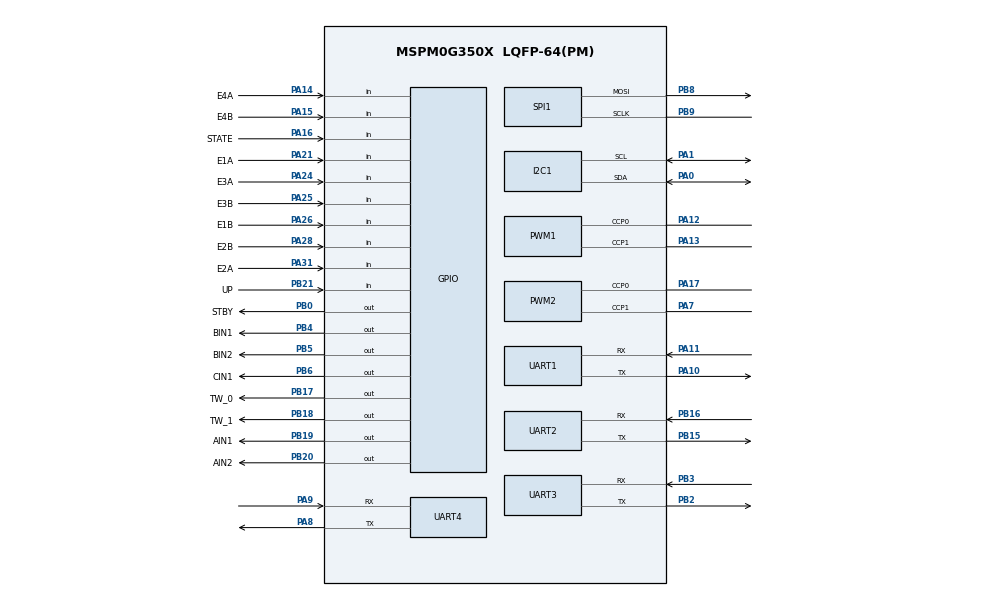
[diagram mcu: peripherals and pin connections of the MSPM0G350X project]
/**
 * @cliArgs --device "MSPM0G350X" --part "Default" --package "LQFP-64(PM)" --product "mspm0_sdk@2.02.00.05"
 * @versions {"tool":"1.21.1+3772"}
 */

/**
 * Import the modules used in this configuration.
 */
const ADC12   = scripting.addModule("/ti/driverlib/ADC12", {}, false);
const ADC121  = ADC12.addInstance();
const GPIO    = scripting.addModule("/ti/driverlib/GPIO", {}, false);
const GPIO1   = GPIO.addInstance();
const GPIO2   = GPIO.addInstance();
const GPIO3   = GPIO.addInstance();
const GPIO4   = GPIO.addInstance();
const GPIO5   = GPIO.addInstance();
const GPIO6   = GPIO.addInstance();
const I2C     = scripting.addModule("/ti/driverlib/I2C", {}, false);
const I2C1    = I2C.addInstance();
const PWM     = scripting.addModule("/ti/driverlib/PWM", {}, false);
const PWM1    = PWM.addInstance();
const PWM2    = PWM.addInstance();
const SPI     = scripting.addModule("/ti/driverlib/SPI", {}, false);
const SPI1    = SPI.addInstance();
const SYSCTL  = scripting.addModule("/ti/driverlib/SYSCTL");
const SYSTICK = scripting.addModule("/ti/driverlib/SYSTICK");
const TIMER   = scripting.addModule("/ti/driverlib/TIMER", {}, false);
const TIMER1  = TIMER.addInstance();
const UART    = scripting.addModule("/ti/driverlib/UART", {}, false);
const UART1   = UART.addInstance();
const UART2   = UART.addInstance();
const UART3   = UART.addInstance();
const UART4   = UART.addInstance();

/**
 * Write custom configuration values to the imported modules.
 */
const divider9       = system.clockTree["UDIV"];
divider9.divideValue = 2;

const gate7  = system.clockTree["MFCLKGATE"];
gate7.enable = true;

const multiplier2         = system.clockTree["PLL_QDIV"];
multiplier2.multiplyValue = 5;

const mux8       = system.clockTree["HSCLKMUX"];
mux8.inputSelect = "HSCLKMUX_SYSPLL0";

ADC121.$name                             = "ADC_VOLTAGE";
ADC121.repeatMode                        = true;
ADC121.adcMem0_name                      = "ADC_CH0";
ADC121.sampClkDiv                        = "DL_ADC12_CLOCK_DIVIDE_8";
ADC121.powerDownMode                     = "DL_ADC12_POWER_DOWN_MODE_MANUAL";
ADC121.sampleTime0                       = "10ms";
ADC121.enabledInterrupts                 = ["DL_ADC12_INTERRUPT_MEM0_RESULT_LOADED"];
ADC121.peripheral.$assign                = "ADC0";
ADC121.peripheral.adcPin0.$assign        = "PA27";
ADC121.adcPin0Config.hideOutputInversion = scripting.forceWrite(false);
ADC121.adcPin0Config.$name               = "ti_driverlib_gpio_GPIOPinGeneric8";

const Board = scripting.addModule("/ti/driverlib/Board", {}, false);

/* LCD data bus: hardware SPI1 (SCLK=PB9, PICO=PB8), MOTO3, POCI unused -> left unassigned */
SPI1.$name                              = "LCD_DATA";
SPI1.frameFormat                        = "MOTO3";
SPI1.direction                          = "PICO";   /* 只发不收: 不占用 POCI, 把 PB21 让给按键 */
SPI1.targetBitRate                      = 32000000;
SPI1.peripheral.$assign                 = "SPI1";
SPI1.peripheral.sclkPin.$assign         = "PB9";
SPI1.peripheral.mosiPin.$assign         = "PB8";
SPI1.sclkPinConfig.direction            = scripting.forceWrite("OUTPUT");
SPI1.sclkPinConfig.onlyInternalResistor = scripting.forceWrite(false);
SPI1.sclkPinConfig.passedPeripheralType = scripting.forceWrite("Digital");
SPI1.mosiPinConfig.direction            = scripting.forceWrite("OUTPUT");
SPI1.mosiPinConfig.hideOutputInversion  = scripting.forceWrite(false);
SPI1.mosiPinConfig.onlyInternalResistor = scripting.forceWrite(false);
SPI1.mosiPinConfig.passedPeripheralType = scripting.forceWrite("Digital");
SPI1.sclkPinConfig.$name                = "ti_driverlib_gpio_GPIOPinGeneric15";
SPI1.mosiPinConfig.$name                = "ti_driverlib_gpio_GPIOPinGeneric16";
GPIO1.$name                          = "LCD";
GPIO1.port                           = "PORTB";
GPIO1.associatedPins.create(4);
GPIO1.associatedPins[0].$name        = "LCD_RES";
GPIO1.associatedPins[0].assignedPort = "PORTB";
GPIO1.associatedPins[0].assignedPin  = "10";
GPIO1.associatedPins[1].$name        = "LCD_DC";
GPIO1.associatedPins[1].assignedPort = "PORTB";
GPIO1.associatedPins[1].assignedPin  = "11";
GPIO1.associatedPins[2].$name        = "LCD_CS";
GPIO1.associatedPins[2].assignedPort = "PORTB";
GPIO1.associatedPins[2].assignedPin  = "14";
GPIO1.associatedPins[3].$name        = "BLK";
GPIO1.associatedPins[3].assignedPort = "PORTB";
GPIO1.associatedPins[3].assignedPin  = "26";
GPIO2.$name                         = "Motor";
GPIO2.port                          = "PORTB";
GPIO2.associatedPins.create(9);
GPIO2.associatedPins[0].$name       = "AIN1";
GPIO2.associatedPins[0].assignedPin = "19";
GPIO2.associatedPins[0].pin.$assign = "PB19";
GPIO2.associatedPins[1].$name       = "AIN2";
GPIO2.associatedPins[1].assignedPin = "20";
GPIO2.associatedPins[1].pin.$assign = "PB20";
GPIO2.associatedPins[2].$name       = "BIN1";
GPIO2.associatedPins[2].assignedPin = "4";
GPIO2.associatedPins[2].pin.$assign = "PB4";
GPIO2.associatedPins[3].$name       = "BIN2";
GPIO2.associatedPins[3].assignedPin = "5";
GPIO2.associatedPins[3].pin.$assign = "PB5";
GPIO2.associatedPins[4].$name       = "CIN1";
GPIO2.associatedPins[4].assignedPin = "6";
GPIO2.associatedPins[4].pin.$assign = "PB6";
GPIO2.associatedPins[5].assignedPin = "7";
GPIO2.associatedPins[5].$name       = "CIN2";
GPIO2.associatedPins[6].assignedPin = "12";
GPIO2.associatedPins[6].$name       = "DIN1";
GPIO2.associatedPins[7].assignedPin = "13";
GPIO2.associatedPins[7].$name       = "DIN2";
GPIO2.associatedPins[8].$name       = "STBY";   /* TB6612 enable, active high */
GPIO2.associatedPins[8].assignedPort = "PORTB";
GPIO2.associatedPins[8].assignedPin = "0";
GPIO2.associatedPins[8].pin.$assign = "PB0";

GPIO3.$name                               = "ENCODER";
GPIO3.associatedPins.create(8);
GPIO3.associatedPins[0].direction         = "INPUT";
GPIO3.associatedPins[0].assignedPort      = "PORTA";
GPIO3.associatedPins[0].assignedPin       = "26";
GPIO3.associatedPins[0].interruptEn       = true;
GPIO3.associatedPins[0].interruptPriority = "0";
GPIO3.associatedPins[0].polarity          = "RISE";
GPIO3.associatedPins[0].$name             = "E1B";
GPIO3.associatedPins[0].pin.$assign       = "PA26";
GPIO3.associatedPins[1].direction         = "INPUT";
GPIO3.associatedPins[1].assignedPort      = "PORTA";
GPIO3.associatedPins[1].assignedPin       = "31";
GPIO3.associatedPins[1].interruptEn       = true;
GPIO3.associatedPins[1].interruptPriority = "0";
GPIO3.associatedPins[1].polarity          = "RISE";
GPIO3.associatedPins[1].$name             = "E2A";
GPIO3.associatedPins[1].pin.$assign       = "PA31";
GPIO3.associatedPins[2].$name             = "E2B";
GPIO3.associatedPins[2].direction         = "INPUT";
GPIO3.associatedPins[2].assignedPort      = "PORTA";
GPIO3.associatedPins[2].assignedPin       = "28";
GPIO3.associatedPins[2].interruptEn       = true;
GPIO3.associatedPins[2].polarity          = "RISE";
GPIO3.associatedPins[2].pin.$assign       = "PA28";
GPIO3.associatedPins[3].assignedPort      = "PORTA";
GPIO3.associatedPins[3].assignedPin       = "24";
GPIO3.associatedPins[3].$name             = "E3A";
GPIO3.associatedPins[3].direction         = "INPUT";
GPIO3.associatedPins[3].interruptEn       = true;
GPIO3.associatedPins[3].polarity          = "RISE";
GPIO3.associatedPins[3].pin.$assign       = "PA24";
GPIO3.associatedPins[4].assignedPort      = "PORTA";
GPIO3.associatedPins[4].assignedPin       = "25";
GPIO3.associatedPins[4].$name             = "E3B";
GPIO3.associatedPins[4].direction         = "INPUT";
GPIO3.associatedPins[4].interruptEn       = true;
GPIO3.associatedPins[4].polarity          = "RISE";
GPIO3.associatedPins[4].pin.$assign       = "PA25";
GPIO3.associatedPins[5].assignedPort      = "PORTA";
GPIO3.associatedPins[5].assignedPin       = "14";
GPIO3.associatedPins[5].direction         = "INPUT";
GPIO3.associatedPins[5].interruptEn       = true;
GPIO3.associatedPins[5].interruptPriority = "0";
GPIO3.associatedPins[5].polarity          = "RISE";
GPIO3.associatedPins[5].$name             = "E4A";
GPIO3.associatedPins[5].pin.$assign       = "PA14";
GPIO3.associatedPins[6].assignedPort      = "PORTA";
GPIO3.associatedPins[6].direction         = "INPUT";
GPIO3.associatedPins[6].assignedPin       = "15";
GPIO3.associatedPins[6].interruptEn       = true;
GPIO3.associatedPins[6].interruptPriority = "0";
GPIO3.associatedPins[6].polarity          = "RISE";
GPIO3.associatedPins[6].$name             = "E4B";
GPIO3.associatedPins[6].pin.$assign       = "PA15";
GPIO3.associatedPins[7].$name             = "E1A";
GPIO3.associatedPins[7].direction         = "INPUT";
GPIO3.associatedPins[7].assignedPort      = "PORTA";
GPIO3.associatedPins[7].interruptEn       = true;
GPIO3.associatedPins[7].polarity          = "RISE";
GPIO3.associatedPins[7].pin.$assign       = "PA21";

GPIO4.$name                          = "HCO5";
GPIO4.associatedPins[0].$name        = "STATE";
GPIO4.associatedPins[0].assignedPort = "PORTA";
GPIO4.associatedPins[0].direction    = "INPUT";
GPIO4.associatedPins[0].assignedPin  = "16";
GPIO4.associatedPins[0].pin.$assign  = "PA16";

GPIO5.$name                          = "TW";
GPIO5.associatedPins.create(2);
GPIO5.associatedPins[0].$name        = "TW_0";
GPIO5.associatedPins[0].assignedPort = "PORTB";
GPIO5.associatedPins[0].pin.$assign  = "PB17";
GPIO5.associatedPins[1].$name        = "TW_1";
GPIO5.associatedPins[1].assignedPort = "PORTB";
GPIO5.associatedPins[1].pin.$assign  = "PB18";
/* 板载按键 S2 = PB21 (按下接 GND, 内部上拉): 单击启停 / 长按加速 */
GPIO6.$name                          = "KEY1";
GPIO6.associatedPins[0].$name        = "UP";
GPIO6.associatedPins[0].assignedPort = "PORTB";
GPIO6.associatedPins[0].direction    = "INPUT";
GPIO6.associatedPins[0].internalResistor = "PULL_UP";
GPIO6.associatedPins[0].assignedPin  = "21";
GPIO6.associatedPins[0].pin.$assign  = "PB21";


I2C1.$name                           = "I2C_0";
I2C1.basicEnableController           = true;
I2C1.basicControllerStandardBusSpeed = "Fast";
I2C1.peripheral.$assign              = "I2C0";
I2C1.peripheral.sdaPin.$assign       = "PA0";
I2C1.peripheral.sclPin.$assign       = "PA1";
I2C1.sdaPinConfig.$name              = "ti_driverlib_gpio_GPIOPinGeneric11";
I2C1.sclPinConfig.$name              = "ti_driverlib_gpio_GPIOPinGeneric12";

PWM1.clockDivider                       = 4;
PWM1.clockPrescale                      = 5;
PWM1.timerStartTimer                    = true;
PWM1.$name                              = "Motor_PWM_Front";
PWM1.clockDivider                       = 4;   /* 80MHz/4/1 = 20MHz -> 20kHz PWM */
PWM1.clockPrescale                      = 1;
PWM1.peripheral.$assign                 = "TIMG0";
PWM1.peripheral.ccp0Pin.$assign         = "PA12";
PWM1.peripheral.ccp1Pin.$assign         = "PA13";
PWM1.PWM_CHANNEL_0.$name                = "ti_driverlib_pwm_PWMTimerCC0";
PWM1.PWM_CHANNEL_0.invert               = true;
PWM1.PWM_CHANNEL_1.$name                = "ti_driverlib_pwm_PWMTimerCC1";
PWM1.PWM_CHANNEL_1.invert               = true;
PWM1.ccp0PinConfig.direction            = scripting.forceWrite("OUTPUT");
PWM1.ccp0PinConfig.hideOutputInversion  = scripting.forceWrite(false);
PWM1.ccp0PinConfig.onlyInternalResistor = scripting.forceWrite(false);
PWM1.ccp0PinConfig.passedPeripheralType = scripting.forceWrite("Digital");
PWM1.ccp0PinConfig.$name                = "ti_driverlib_gpio_GPIOPinGeneric2";
PWM1.ccp1PinConfig.direction            = scripting.forceWrite("OUTPUT");
PWM1.ccp1PinConfig.hideOutputInversion  = scripting.forceWrite(false);
PWM1.ccp1PinConfig.onlyInternalResistor = scripting.forceWrite(false);
PWM1.ccp1PinConfig.passedPeripheralType = scripting.forceWrite("Digital");
PWM1.ccp1PinConfig.$name                = "ti_driverlib_gpio_GPIOPinGeneric3";

PWM2.$name                              = "Motor_PWM_Back";
PWM2.clockDivider                       = 4;
PWM2.clockPrescale                      = 1;   /* 20MHz -> 20kHz, same as front */
PWM2.timerStartTimer                    = true;
PWM2.peripheral.$assign                 = "TIMG7";
PWM2.peripheral.ccp0Pin.$assign         = "PA17";
PWM2.peripheral.ccp1Pin.$assign         = "PA7";
PWM2.PWM_CHANNEL_0.$name                = "ti_driverlib_pwm_PWMTimerCC2";
PWM2.PWM_CHANNEL_0.invert               = true;
PWM2.PWM_CHANNEL_1.$name                = "ti_driverlib_pwm_PWMTimerCC3";
PWM2.PWM_CHANNEL_1.invert               = true;
PWM2.ccp0PinConfig.direction            = scripting.forceWrite("OUTPUT");
PWM2.ccp0PinConfig.hideOutputInversion  = scripting.forceWrite(false);
PWM2.ccp0PinConfig.onlyInternalResistor = scripting.forceWrite(false);
PWM2.ccp0PinConfig.passedPeripheralType = scripting.forceWrite("Digital");
PWM2.ccp0PinConfig.$name                = "ti_driverlib_gpio_GPIOPinGeneric4";
PWM2.ccp1PinConfig.direction            = scripting.forceWrite("OUTPUT");
PWM2.ccp1PinConfig.hideOutputInversion  = scripting.forceWrite(false);
PWM2.ccp1PinConfig.onlyInternalResistor = scripting.forceWrite(false);
PWM2.ccp1PinConfig.passedPeripheralType = scripting.forceWrite("Digital");
PWM2.ccp1PinConfig.$name                = "ti_driverlib_gpio_GPIOPinGeneric5";

SYSCTL.forceDefaultClkConfig = true;
SYSCTL.clockTreeEn           = true;

SYSTICK.periodEnable  = true;
SYSTICK.period        = 80;
SYSTICK.systickEnable = true;

TIMER1.$name              = "TIMER_0";
TIMER1.timerClkDiv        = 8;
TIMER1.timerPeriod        = "1 ms";
TIMER1.timerMode          = "PERIODIC";
TIMER1.timerStartTimer    = true;
TIMER1.interrupts         = ["ZERO"];
TIMER1.peripheral.$assign = "TIMG6";

UART1.$name                    = "UART_0";
UART1.targetBaudRate           = 115200;
UART1.uartClkDiv               = "5";
UART1.enabledInterrupts        = ["RX"];
UART1.peripheral.$assign       = "UART0";
UART1.peripheral.rxPin.$assign = "PA11";
UART1.peripheral.txPin.$assign = "PA10";
UART1.txPinConfig.$name        = "ti_driverlib_gpio_GPIOPinGeneric0";
UART1.rxPinConfig.enableConfig = true;
UART1.rxPinConfig.internalResistor = "PULL_UP";   /* RX idle high when floating */
UART1.rxPinConfig.$name        = "ti_driverlib_gpio_GPIOPinGeneric1";

UART2.$name                            = "UART_2";
UART2.enabledInterrupts                = ["RX"];
UART2.targetBaudRate                   = 115200;
UART2.uartClkDiv                       = "5";
UART2.peripheral.$assign               = "UART2";
UART2.peripheral.rxPin.$assign         = "PB16";
UART2.peripheral.txPin.$assign         = "PB15";
UART2.txPinConfig.direction            = scripting.forceWrite("OUTPUT");
UART2.txPinConfig.hideOutputInversion  = scripting.forceWrite(false);
UART2.txPinConfig.onlyInternalResistor = scripting.forceWrite(false);
UART2.txPinConfig.passedPeripheralType = scripting.forceWrite("Digital");
UART2.txPinConfig.$name                = "ti_driverlib_gpio_GPIOPinGeneric6";
UART2.rxPinConfig.hideOutputInversion  = scripting.forceWrite(false);
UART2.rxPinConfig.onlyInternalResistor = scripting.forceWrite(false);
UART2.rxPinConfig.passedPeripheralType = scripting.forceWrite("Digital");
UART2.rxPinConfig.enableConfig = true;
UART2.rxPinConfig.internalResistor = "PULL_UP";   /* RX idle high when floating */
UART2.rxPinConfig.$name                = "ti_driverlib_gpio_GPIOPinGeneric7";

UART3.$name                            = "LORA";
UART3.enabledInterrupts                = ["RX"];
UART3.uartClkDiv                       = "5";
UART3.peripheral.$assign               = "UART3";
UART3.peripheral.rxPin.$assign         = "PB3";
UART3.peripheral.txPin.$assign         = "PB2";
UART3.txPinConfig.direction            = scripting.forceWrite("OUTPUT");
UART3.txPinConfig.hideOutputInversion  = scripting.forceWrite(false);
UART3.txPinConfig.onlyInternalResistor = scripting.forceWrite(false);
UART3.txPinConfig.passedPeripheralType = scripting.forceWrite("Digital");
UART3.txPinConfig.$name                = "ti_driverlib_gpio_GPIOPinGeneric9";
UART3.rxPinConfig.hideOutputInversion  = scripting.forceWrite(false);
UART3.rxPinConfig.onlyInternalResistor = scripting.forceWrite(false);
UART3.rxPinConfig.passedPeripheralType = scripting.forceWrite("Digital");
UART3.rxPinConfig.enableConfig = true;
UART3.rxPinConfig.internalResistor = "PULL_UP";   /* RX idle high when floating */
UART3.rxPinConfig.$name                = "ti_driverlib_gpio_GPIOPinGeneric10";

UART4.targetBaudRate                   = 115200;
UART4.uartClkDiv                       = "5";
UART4.$name                            = "IMU";
UART4.enabledInterrupts                = ["RX"];
UART4.peripheral.$assign               = "UART1";
UART4.peripheral.rxPin.$assign         = "PA9";
UART4.peripheral.txPin.$assign         = "PA8";
UART4.txPinConfig.$name                = "ti_driverlib_gpio_GPIOPinGeneric13";
UART4.txPinConfig.direction            = scripting.forceWrite("OUTPUT");
UART4.txPinConfig.hideOutputInversion  = scripting.forceWrite(false);
UART4.txPinConfig.onlyInternalResistor = scripting.forceWrite(false);
UART4.txPinConfig.passedPeripheralType = scripting.forceWrite("Digital");
UART4.rxPinConfig.enableConfig = true;
UART4.rxPinConfig.internalResistor = "PULL_UP";   /* RX idle high when floating */
UART4.rxPinConfig.$name                = "ti_driverlib_gpio_GPIOPinGeneric14";
UART4.rxPinConfig.hideOutputInversion  = scripting.forceWrite(false);
UART4.rxPinConfig.onlyInternalResistor = scripting.forceWrite(false);
UART4.rxPinConfig.passedPeripheralType = scripting.forceWrite("Digital");

/**
 * Pinmux solution for unlocked pins/peripherals. This ensures that minor changes to the automatic solver in a future
 * version of the tool will not impact the pinmux you originally saw.  These lines can be completely deleted in order to
 * re-solve from scratch.
 */
Board.peripheral.$suggestSolution            = "DEBUGSS";
Board.peripheral.swclkPin.$suggestSolution   = "PA20";
Board.peripheral.swdioPin.$suggestSolution   = "PA19";
GPIO1.associatedPins[0].pin.$suggestSolution = "PB10";
GPIO1.associatedPins[1].pin.$suggestSolution = "PB11";
GPIO1.associatedPins[2].pin.$suggestSolution = "PB14";
GPIO1.associatedPins[3].pin.$suggestSolution = "PB26";
SPI1.peripheral.$suggestSolution           = "SPI1";
GPIO2.associatedPins[5].pin.$suggestSolution = "PB7";
GPIO2.associatedPins[6].pin.$suggestSolution = "PB12";
GPIO2.associatedPins[7].pin.$suggestSolution = "PB13";
